# Cortex_M52 register map
Vendor: Arm Ltd.; Series: ARMv8.1-M Mainline; File version: 1.0.0
CPU: other r0p0, little endian, MPU, FPU, double-precision FPU, DSP, 8 interrupt priority bits
Registers are 32-bit, read-write, reset 0x0 unless marked. A register's access mark holds for its fields unless they carry their own. Offsets are from the block's base; [hi:lo] are bit positions; {n}, {i} and the like mark numbered series.

## CTI — Cross Trigger Interface (CoreSight CTI, optional): routes debug events (halt, restart, DWT/ETM triggers) between the core and the rest of the SoC over four cross-trigger channels. Cortex-M33/M55/M85 implement 8 triggers in and out.
Base 0xE0042000
0x00 CTICONTROL
  [0] GLBEN — Global enable: 1 = the CTI passes trigger events to and from the channels.
0x10 CTIINTACK wo — CTI Interrupt Acknowledge Register: write 1 to clear an active trigger output (needed for level-sensitive outputs such as the debug request).
  [7:0] INTACK — Bit n acknowledges trigger output n.
0x14 CTIAPPSET — CTI Application Trigger Set Register: software-generated channel events.
  [3:0] APPSET — Write 1 to bit n to raise an event on channel n; reads the current application trigger state.
0x18 CTIAPPCLEAR wo — CTI Application Trigger Clear Register.
  [3:0] APPCLEAR — Write 1 to bit n to clear the application trigger on channel n.
0x1C CTIAPPPULSE wo — CTI Application Pulse Register: one-cycle channel event.
  [3:0] APPULSE — Write 1 to bit n to pulse channel n.
{0x20+4i} CTIINEN{i} (i=0..7) — CTI Trigger to Channel Enable Register n: which channels trigger input n drives. Cortex-M trigger inputs: 0 core halted, 1 DWT comparator 0, 2 DWT comparator 1, 3 DWT comparator 2, 4 ETM event 0, 5 ETM event 1, 6-7 implementation defined.
  [3:0] TRIGINEN — Bit k: trigger input n generates an event on channel k.
{0xA0+4i} CTIOUTEN{i} (i=0..7) — CTI Channel to Trigger Enable Register n: which channels drive trigger output n. Cortex-M trigger outputs: 0 debug request (halt), 1 restart, 2-3 CTI interrupts, 4-7 ETM external inputs / implementation defined.
  [3:0] TRIGOUTEN — Bit k: an event on channel k asserts trigger output n.
0x130 CTITRIGINSTATUS ro — CTI Trigger In Status Register.
  [7:0] TRIGINSTATUS — Bit n: trigger input n is asserted.
0x134 CTITRIGOUTSTATUS ro — CTI Trigger Out Status Register.
  [7:0] TRIGOUTSTATUS — Bit n: trigger output n is asserted.
0x138 CTICHINSTATUS ro — CTI Channel In Status Register.
  [3:0] CTICHINSTATUS — Bit k: channel k input is active.
0x13C CTICHOUTSTATUS ro — CTI Channel Out Status Register.
  [3:0] CTICHOUTSTATUS — Bit k: channel k output is active.
0x140 CTIGATE — CTI Channel Gate Enable Register: which channels propagate to the external cross-trigger matrix. Reset value 0xF (all open).
  [3:0] CTIGATEEN — Bit k: 1 = channel k events pass to/from the CTM, 0 = channel k is internal to this CTI.
0x144 ASICCTL — External Multiplexer Control Register (implementation defined; reserved on Cortex-M).
0xEE4 ITCHOUT — Integration Test Channel Output Register (integration mode only).
0xEE8 ITTRIGOUT — Integration Test Trigger Output Register (integration mode only).
0xEF4 ITCHIN ro — Integration Test Channel Input Register (integration mode only).
0xEF8 ITTRIGIN ro — Integration Test Trigger Input Register (integration mode only).
0xF00 ITCTRL — Integration Mode Control Register.
  [0] IME — Integration mode enable: 1 = the IT* registers drive and observe the CTI ports.
0xFA0 CLAIMSET — Claim Tag Set Register: reads the implemented claim bits (1 = implemented), write 1 to set a claim bit. Used by debuggers and software to negotiate ownership.
0xFA4 CLAIMCLR — Claim Tag Clear Register: reads the current claim tag, write 1 to clear a claim bit.
0xFA8 DEVAFF0 ro — Device Affinity Register 0 (implementation defined).
0xFAC DEVAFF1 ro — Device Affinity Register 1 (implementation defined).
0xFB0 LAR wo — Lock Access Register: write 0xC5ACCE55 to unlock the component for software (not debugger) writes.
  [31:0] KEY — Write 0xC5ACCE55 to unlock, any other value to lock.
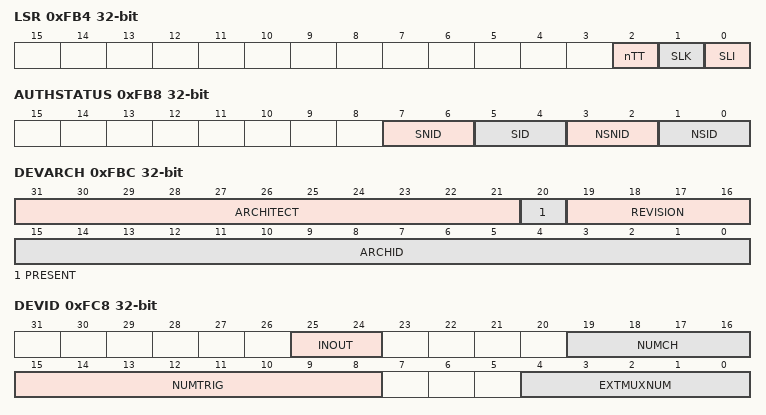
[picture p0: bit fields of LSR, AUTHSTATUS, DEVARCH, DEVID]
0xFB4 LSR ro — Lock Status Register.
  [2] nTT — Not thirty-two bit: 0 = the lock register is 32-bit.
  [1] SLK — Software lock status: 1 = locked, writes from software are ignored.
  [0] SLI — Software lock implemented.
0xFB8 AUTHSTATUS ro — Authentication Status Register: which debug and trace features the DAUTH/SPIDEN inputs currently permit.
  [7:6] SNID — Secure non-invasive debug.
  [5:4] SID — Secure invasive debug.
  [3:2] NSNID — Non-secure non-invasive debug.
  [1:0] NSID — Non-secure invasive debug: 0b10 disabled, 0b11 enabled.
0xFBC DEVARCH ro — Device Architecture Register: the architecture of the component (CoreSight ARCHID) and its architect.
  [31:21] ARCHITECT — JEP106 code of the architect (Arm: 0x23B).
  [20] PRESENT — 1 = DEVARCH is present and its contents are valid.
  [19:16] REVISION — Architecture revision.
  [15:0] ARCHID — Architecture ID, including the architecture part number [11:0] and revision [15:12].
0xFC0 DEVID2 ro — Device Configuration Register 2 (reserved).
0xFC4 DEVID1 ro — Device Configuration Register 1 (reserved).
0xFC8 DEVID ro — Device Configuration Register: CTI topology.
  [25:24] INOUT — Input/output options: 0 = no CTIGATE mask on CTM.
  [19:16] NUMCH — Number of channels implemented.
  [15:8] NUMTRIG — Number of triggers implemented.
  [4:0] EXTMUXNUM — Number of multiplexers on the trigger inputs and outputs (0 on Cortex-M).
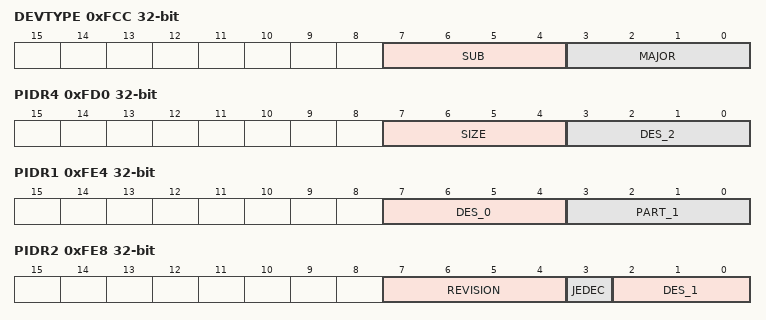
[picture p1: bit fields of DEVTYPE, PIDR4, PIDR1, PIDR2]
0xFCC DEVTYPE ro — Device Type Register: major and sub type of the CoreSight component.
  [7:4] SUB — Sub type within the major class.
  [3:0] MAJOR — Major type: 0 miscellaneous, 1 trace sink, 2 trace link, 3 trace source, 4 debug control, 5 debug logic, 6 PMU.
0xFD0 PIDR4 ro — Peripheral Identification Register 4: JEP106 continuation code and component size.
  [7:4] SIZE — Log2 of the number of 4 KB blocks the component occupies (0 = one block).
  [3:0] DES_2 — JEP106 continuation code of the designer (Arm: 0x4).
{0xFC0+4i} PIDR{i} ro (i=5..7) — Peripheral Identification Register {i} (reserved, reads as zero).
0xFE0 PIDR0 ro — Peripheral Identification Register 0: part number bits [7:0].
  [7:0] PART_0 — Part number bits [7:0].
0xFE4 PIDR1 ro — Peripheral Identification Register 1: part number bits [11:8] and designer bits [3:0].
  [7:4] DES_0 — JEP106 identity code bits [3:0] of the designer.
  [3:0] PART_1 — Part number bits [11:8].
0xFE8 PIDR2 ro — Peripheral Identification Register 2: designer bits [6:4], JEDEC flag and revision.
  [7:4] REVISION — Component major revision.
  [3] JEDEC — Always 1: the designer ID is a JEDEC JEP106 code.
  [2:0] DES_1 — JEP106 identity code bits [6:4] of the designer.
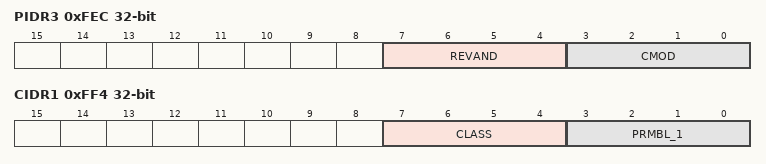
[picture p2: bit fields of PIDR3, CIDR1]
0xFEC PIDR3 ro — Peripheral Identification Register 3: customer modified and minor revision.
  [7:4] REVAND — Minor revision (metal fix) number.
  [3:0] CMOD — Customer Modified: 0 if the component has not been modified by the integrator.
0xFF0 CIDR0 ro — Component Identification Register 0: preamble byte 0 (0x0D).
  [7:0] PRMBL_0 — Preamble, reads as 0x0D.
0xFF4 CIDR1 ro — Component Identification Register 1: component class and preamble.
  [7:4] CLASS — Component class: 0x1 ROM table, 0x9 CoreSight component, 0xE generic IP, 0xF CoreLink/PrimeCell.
  [3:0] PRMBL_1 — Preamble, reads as 0x0.
0xFF8 CIDR2 ro — Component Identification Register 2: preamble byte 2 (0x05).
  [7:0] PRMBL_2 — Preamble, reads as 0x05.
0xFFC CIDR3 ro — Component Identification Register 3: preamble byte 3 (0xB1).
  [7:0] PRMBL_3 — Preamble, reads as 0xB1.
